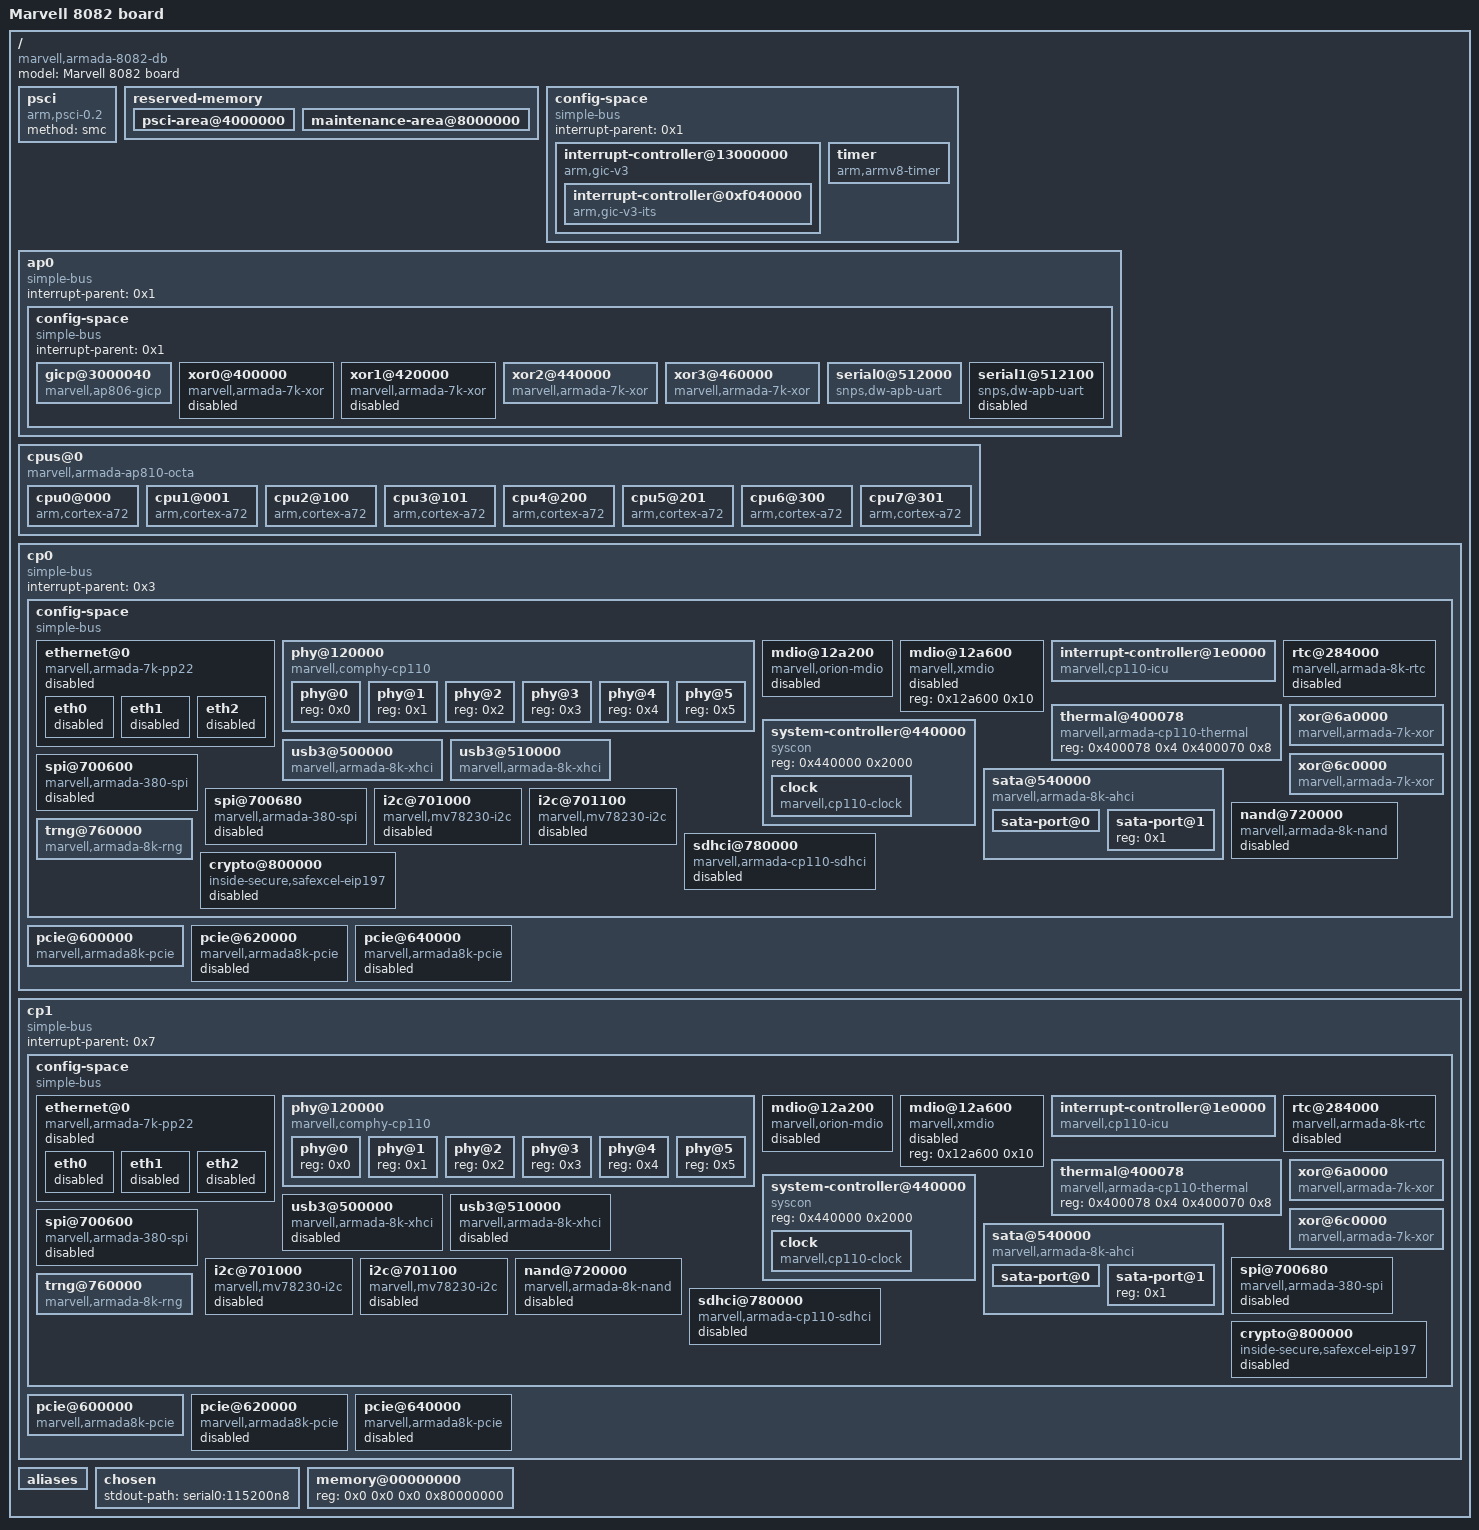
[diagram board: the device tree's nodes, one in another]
/dts-v1/;

/ {
    model = "Marvell 8082 board";
    compatible = "marvell,armada-8082-db", "marvell,armada-8082", "marvell,armada-ap810-octa", "marvell,armada-ap810";
    #address-cells = <0x2>;
    #size-cells = <0x2>;

    psci {
        compatible = "arm,psci-0.2";
        method = "smc";
    };

    reserved-memory {
        #address-cells = <0x2>;
        #size-cells = <0x2>;
        ranges;

        psci-area@4000000 {
            reg = <0x0 0x4000000 0x0 0x200000>;
            no-map;
        };

        maintenance-area@8000000 {
            reg = <0x0 0x8000000 0x0 0x100000>;
            no-map;
        };
    };

    config-space {
        #address-cells = <0x1>;
        #size-cells = <0x1>;
        compatible = "simple-bus";
        ranges = <0x0 0x0 0xdc000000 0x14000000>;
        interrupt-parent = <0x1>;

        interrupt-controller@13000000 {
            compatible = "arm,gic-v3";
            #interrupt-cells = <0x3>;
            #address-cells = <0x1>;
            #size-cells = <0x1>;
            interrupt-controller;
            interrupts = <0x1 0x9 0x4>;
            ranges;
            reg = <0x13000000 0x10000 0x13060000 0x100000 0x100c0000 0x2000 0x100d0000 0x1000 0x100e0000 0x2000>;
            linux,phandle = <0x1>;
            phandle = <0x1>;

            interrupt-controller@0xf040000 {
                compatible = "arm,gic-v3-its";
                msi-controller;
                #msi-cells = <0x1>;
                reg = <0xf040000 0x20000>;
                linux,phandle = <0x2>;
                phandle = <0x2>;
            };
        };

        timer {
            compatible = "arm,armv8-timer";
            interrupts = <0x1 0xd 0x8 0x1 0xe 0x8 0x1 0xb 0x8 0x1 0xa 0x8>;
        };
    };

    ap0 {
        #address-cells = <0x2>;
        #size-cells = <0x2>;
        compatible = "simple-bus";
        interrupt-parent = <0x1>;
        ranges;

        config-space {
            #address-cells = <0x1>;
            #size-cells = <0x1>;
            compatible = "simple-bus";
            ranges = <0x0 0x0 0xe8000000 0x4000000>;
            interrupt-parent = <0x1>;

            gicp@3000040 {
                compatible = "marvell,ap806-gicp";
                reg = <0x3000040 0x10>;
                marvell,spi-ranges = <0x5c 0x40 0x9c 0x40>;
                msi-controller;
                linux,phandle = <0x6>;
                phandle = <0x6>;
            };

            xor0@400000 {
                compatible = "marvell,armada-7k-xor", "marvell,xor-v2";
                reg = <0x400000 0x1000 0x410000 0x1000>;
                msi-parent = <0x2 0x100>;
                dma-coherent;
                status = "disabled";
            };

            xor1@420000 {
                compatible = "marvell,armada-7k-xor", "marvell,xor-v2";
                reg = <0x420000 0x1000 0x430000 0x1000>;
                msi-parent = <0x2 0x101>;
                dma-coherent;
                status = "disabled";
            };

            xor2@440000 {
                compatible = "marvell,armada-7k-xor", "marvell,xor-v2";
                reg = <0x440000 0x1000 0x450000 0x1000>;
                msi-parent = <0x2 0x102>;
                dma-coherent;
            };

            xor3@460000 {
                compatible = "marvell,armada-7k-xor", "marvell,xor-v2";
                reg = <0x460000 0x1000 0x470000 0x1000>;
                msi-parent = <0x2 0x103>;
                dma-coherent;
            };

            serial0@512000 {
                compatible = "snps,dw-apb-uart";
                reg = <0x512000 0x100>;
                reg-shift = <0x2>;
                interrupts = <0x0 0x16 0x4>;
                reg-io-width = <0x1>;
                status = "okay";
                clock-frequency = <0xbebc200>;
            };

            serial1@512100 {
                compatible = "snps,dw-apb-uart";
                reg = <0x512100 0x100>;
                reg-shift = <0x2>;
                interrupts = <0x0 0x17 0x4>;
                reg-io-width = <0x1>;
                status = "disabled";
            };
        };
    };

    cpus@0 {
        #address-cells = <0x1>;
        #size-cells = <0x0>;
        compatible = "marvell,armada-ap810-octa";

        cpu0@000 {
            device_type = "cpu";
            compatible = "arm,cortex-a72", "arm,armv8";
            reg = <0x0>;
            enable-method = "psci";
            numa-node-id = <0x0>;
        };

        cpu1@001 {
            device_type = "cpu";
            compatible = "arm,cortex-a72", "arm,armv8";
            reg = <0x1>;
            enable-method = "psci";
            numa-node-id = <0x0>;
        };

        cpu2@100 {
            device_type = "cpu";
            compatible = "arm,cortex-a72", "arm,armv8";
            reg = <0x100>;
            enable-method = "psci";
            numa-node-id = <0x0>;
        };

        cpu3@101 {
            device_type = "cpu";
            compatible = "arm,cortex-a72", "arm,armv8";
            reg = <0x101>;
            enable-method = "psci";
            numa-node-id = <0x0>;
        };

        cpu4@200 {
            device_type = "cpu";
            compatible = "arm,cortex-a72", "arm,armv8";
            reg = <0x200>;
            enable-method = "psci";
            numa-node-id = <0x0>;
        };

        cpu5@201 {
            device_type = "cpu";
            compatible = "arm,cortex-a72", "arm,armv8";
            reg = <0x201>;
            enable-method = "psci";
            numa-node-id = <0x0>;
        };

        cpu6@300 {
            device_type = "cpu";
            compatible = "arm,cortex-a72", "arm,armv8";
            reg = <0x300>;
            enable-method = "psci";
            numa-node-id = <0x0>;
        };

        cpu7@301 {
            device_type = "cpu";
            compatible = "arm,cortex-a72", "arm,armv8";
            reg = <0x301>;
            enable-method = "psci";
            numa-node-id = <0x0>;
        };
    };

    cp0 {
        #address-cells = <0x2>;
        #size-cells = <0x2>;
        compatible = "simple-bus";
        interrupt-parent = <0x3>;
        ranges;

        config-space {
            #address-cells = <0x1>;
            #size-cells = <0x1>;
            compatible = "simple-bus";
            ranges = <0x0 0x81 0x0 0x2000000>;

            ethernet@0 {
                compatible = "marvell,armada-7k-pp22";
                reg = <0x0 0x100000 0x129000 0xb000>;
                clocks = <0x4 0x1 0x3 0x4 0x1 0x9 0x4 0x1 0x5 0x4 0x1 0x12>;
                clock-names = "pp_clk", "gop_clk", "mg_clk", "axi_clk";
                marvell,system-controller = <0x5>;
                status = "disabled";
                dma-coherent;

                eth0 {
                    interrupts = <0x0 0x27 0x4 0x0 0x2b 0x4 0x0 0x2f 0x4 0x0 0x33 0x4 0x0 0x37 0x4 0x0 0x81 0x4>;
                    interrupt-names = "tx-cpu0", "tx-cpu1", "tx-cpu2", "tx-cpu3", "rx-shared", "link";
                    port-id = <0x0>;
                    gop-port-id = <0x0>;
                    status = "disabled";
                };

                eth1 {
                    interrupts = <0x0 0x28 0x4 0x0 0x2c 0x4 0x0 0x30 0x4 0x0 0x34 0x4 0x0 0x38 0x4 0x0 0x80 0x4>;
                    interrupt-names = "tx-cpu0", "tx-cpu1", "tx-cpu2", "tx-cpu3", "rx-shared", "link";
                    port-id = <0x1>;
                    gop-port-id = <0x2>;
                    status = "disabled";
                };

                eth2 {
                    interrupts = <0x0 0x29 0x4 0x0 0x2d 0x4 0x0 0x31 0x4 0x0 0x35 0x4 0x0 0x39 0x4 0x0 0x7f 0x4>;
                    interrupt-names = "tx-cpu0", "tx-cpu1", "tx-cpu2", "tx-cpu3", "rx-shared", "link";
                    port-id = <0x2>;
                    gop-port-id = <0x3>;
                    status = "disabled";
                };
            };

            phy@120000 {
                compatible = "marvell,comphy-cp110";
                reg = <0x120000 0x6000>;
                marvell,system-controller = <0x5>;
                #address-cells = <0x1>;
                #size-cells = <0x0>;

                phy@0 {
                    reg = <0x0>;
                    #phy-cells = <0x1>;
                };

                phy@1 {
                    reg = <0x1>;
                    #phy-cells = <0x1>;
                };

                phy@2 {
                    reg = <0x2>;
                    #phy-cells = <0x1>;
                };

                phy@3 {
                    reg = <0x3>;
                    #phy-cells = <0x1>;
                };

                phy@4 {
                    reg = <0x4>;
                    #phy-cells = <0x1>;
                };

                phy@5 {
                    reg = <0x5>;
                    #phy-cells = <0x1>;
                };
            };

            mdio@12a200 {
                #address-cells = <0x1>;
                #size-cells = <0x0>;
                compatible = "marvell,orion-mdio";
                reg = <0x12a200 0x10>;
                clocks = <0x4 0x1 0x9 0x4 0x1 0x5 0x4 0x1 0x6 0x4 0x1 0x12>;
                status = "disabled";
            };

            mdio@12a600 {
                #address-cells = <0x1>;
                #size-cells = <0x0>;
                compatible = "marvell,xmdio";
                reg = <0x12a600 0x10>;
                status = "disabled";
            };

            interrupt-controller@1e0000 {
                compatible = "marvell,cp110-icu";
                reg = <0x1e0000 0x10>;
                #interrupt-cells = <0x3>;
                interrupt-controller;
                msi-parent = <0x6>;
                linux,phandle = <0x3>;
                phandle = <0x3>;
            };

            rtc@284000 {
                compatible = "marvell,armada-8k-rtc";
                reg = <0x284000 0x20 0x284080 0x24>;
                reg-names = "rtc", "rtc-soc";
                interrupts = <0x0 0x4d 0x4>;
                status = "disabled";
            };

            thermal@400078 {
                compatible = "marvell,armada-cp110-thermal";
                reg = <0x400078 0x4 0x400070 0x8>;
            };

            system-controller@440000 {
                compatible = "syscon", "simple-mfd";
                reg = <0x440000 0x2000>;
                linux,phandle = <0x5>;
                phandle = <0x5>;

                clock {
                    compatible = "marvell,cp110-clock";
                    #clock-cells = <0x2>;
                    linux,phandle = <0x4>;
                    phandle = <0x4>;
                };
            };

            usb3@500000 {
                compatible = "marvell,armada-8k-xhci", "generic-xhci";
                reg = <0x500000 0x4000>;
                dma-coherent;
                interrupts = <0x0 0x6a 0x4>;
                clocks = <0x4 0x1 0x16>;
                status = "okay";
            };

            usb3@510000 {
                compatible = "marvell,armada-8k-xhci", "generic-xhci";
                reg = <0x510000 0x4000>;
                dma-coherent;
                interrupts = <0x0 0x69 0x4>;
                clocks = <0x4 0x1 0x17>;
                status = "okay";
            };

            sata@540000 {
                compatible = "marvell,armada-8k-ahci", "generic-ahci";
                reg = <0x540000 0x30000>;
                dma-coherent;
                interrupts = <0x0 0x6b 0x4>;
                clocks = <0x4 0x1 0xf>;
                status = "okay";
                #address-cells = <0x1>;
                #size-cells = <0x0>;

                sata-port@0 {
                    reg = <0x0>;
                    satus = "disabled";
                };

                sata-port@1 {
                    reg = <0x1>;
                    status = "okay";
                };
            };

            xor@6a0000 {
                compatible = "marvell,armada-7k-xor", "marvell,xor-v2";
                reg = <0x6a0000 0x1000 0x6b0000 0x1000>;
                dma-coherent;
                msi-parent = <0x2 0x89>;
                clocks = <0x4 0x1 0x8>;
            };

            xor@6c0000 {
                compatible = "marvell,armada-7k-xor", "marvell,xor-v2";
                reg = <0x6c0000 0x1000 0x6d0000 0x1000>;
                dma-coherent;
                msi-parent = <0x2 0x8a>;
                clocks = <0x4 0x1 0x7>;
            };

            spi@700600 {
                compatible = "marvell,armada-380-spi";
                reg = <0x700600 0x50>;
                #address-cells = <0x1>;
                #size-cells = <0x0>;
                cell-index = <0x1>;
                clocks = <0x4 0x1 0x15>;
                status = "disabled";
            };

            spi@700680 {
                compatible = "marvell,armada-380-spi";
                reg = <0x700680 0x50>;
                #address-cells = <0x1>;
                #size-cells = <0x0>;
                cell-index = <0x2>;
                clocks = <0x4 0x1 0x15>;
                status = "disabled";
            };

            i2c@701000 {
                compatible = "marvell,mv78230-i2c";
                reg = <0x701000 0x20>;
                #address-cells = <0x1>;
                #size-cells = <0x0>;
                interrupts = <0x0 0x78 0x4>;
                clocks = <0x4 0x1 0x15>;
                status = "disabled";
            };

            i2c@701100 {
                compatible = "marvell,mv78230-i2c";
                reg = <0x701100 0x20>;
                #address-cells = <0x1>;
                #size-cells = <0x0>;
                interrupts = <0x0 0x79 0x4>;
                clocks = <0x4 0x1 0x15>;
                status = "disabled";
            };

            nand@720000 {
                compatible = "marvell,armada-8k-nand", "marvell,armada370-nand";
                reg = <0x720000 0x54>;
                #address-cells = <0x1>;
                #size-cells = <0x1>;
                interrupts = <0x0 0x73 0x4>;
                clocks = <0x4 0x1 0x2>;
                marvell,system-controller = <0x5>;
                status = "disabled";
            };

            trng@760000 {
                compatible = "marvell,armada-8k-rng", "inside-secure,safexcel-eip76";
                reg = <0x760000 0x7d>;
                interrupts = <0x0 0x5f 0x4>;
                clocks = <0x4 0x1 0x19>;
                status = "okay";
            };

            sdhci@780000 {
                compatible = "marvell,armada-cp110-sdhci";
                reg = <0x780000 0x300>;
                interrupts = <0x0 0x1b 0x4>;
                clock-names = "core", "axi";
                clocks = <0x4 0x1 0x4 0x4 0x1 0x12>;
                dma-coherent;
                status = "disabled";
            };

            crypto@800000 {
                compatible = "inside-secure,safexcel-eip197";
                reg = <0x800000 0x200000>;
                interrupts = <0x0 0x57 0x4 0x0 0x58 0x4 0x0 0x59 0x4 0x0 0x5a 0x4 0x0 0x5b 0x4 0x0 0x5c 0x4>;
                interrupt-names = "mem", "ring0", "ring1", "ring2", "ring3", "eip";
                clocks = <0x4 0x1 0x1a>;
                dma-coherent;
                status = "disabled";
            };
        };

        pcie@600000 {
            compatible = "marvell,armada8k-pcie", "snps,dw-pcie";
            reg = <0x81 0x600000 0x0 0x10000 0x82 0xfff00000 0x0 0x80000>;
            reg-names = "ctrl", "config";
            #address-cells = <0x3>;
            #size-cells = <0x2>;
            #interrupt-cells = <0x1>;
            device_type = "pci";
            dma-coherent;
            msi-parent = <0x2>;
            bus-range = <0x0 0xff>;
            ranges = <0x81000000 0x0 0xfffe0000 0x82 0xfffe0000 0x0 0x10000 0x83000000 0x0 0x0 0x82 0x0 0x0 0xfff00000>;
            interrupt-map-mask = <0x0 0x0 0x0 0x0>;
            interrupt-map = <0x0 0x0 0x0 0x0 0x3 0x0 0x16 0x4>;
            interrupts = <0x0 0x16 0x4>;
            num-lanes = <0x1>;
            clocks = <0x4 0x1 0xd>;
            status = "okay";
        };

        pcie@620000 {
            compatible = "marvell,armada8k-pcie", "snps,dw-pcie";
            reg = <0x81 0x620000 0x0 0x10000 0x84 0xfff00000 0x0 0x80000>;
            reg-names = "ctrl", "config";
            #address-cells = <0x3>;
            #size-cells = <0x2>;
            #interrupt-cells = <0x1>;
            device_type = "pci";
            dma-coherent;
            msi-parent = <0x2>;
            bus-range = <0x0 0xff>;
            ranges = <0x81000000 0x0 0xfffe0000 0x84 0xfffe0000 0x0 0x10000 0x83000000 0x0 0x0 0x84 0x0 0x0 0xfff00000>;
            interrupt-map-mask = <0x0 0x0 0x0 0x0>;
            interrupt-map = <0x0 0x0 0x0 0x0 0x3 0x0 0x18 0x4>;
            interrupts = <0x0 0x18 0x4>;
            num-lanes = <0x1>;
            clocks = <0x4 0x1 0xb>;
            status = "disabled";
        };

        pcie@640000 {
            compatible = "marvell,armada8k-pcie", "snps,dw-pcie";
            reg = <0x81 0x640000 0x0 0x10000 0x86 0xfff00000 0x0 0x80000>;
            reg-names = "ctrl", "config";
            #address-cells = <0x3>;
            #size-cells = <0x2>;
            #interrupt-cells = <0x1>;
            device_type = "pci";
            dma-coherent;
            msi-parent = <0x2>;
            bus-range = <0x0 0xff>;
            ranges = <0x81000000 0x0 0xfffe0000 0x86 0xfffe0000 0x0 0x10000 0x83000000 0x0 0x0 0x86 0x0 0x0 0xfff00000>;
            interrupt-map-mask = <0x0 0x0 0x0 0x0>;
            interrupt-map = <0x0 0x0 0x0 0x0 0x3 0x0 0x17 0x4>;
            interrupts = <0x0 0x17 0x4>;
            num-lanes = <0x1>;
            clocks = <0x4 0x1 0xc>;
            status = "disabled";
        };
    };

    cp1 {
        #address-cells = <0x2>;
        #size-cells = <0x2>;
        compatible = "simple-bus";
        interrupt-parent = <0x7>;
        ranges;

        config-space {
            #address-cells = <0x1>;
            #size-cells = <0x1>;
            compatible = "simple-bus";
            ranges = <0x0 0x88 0x0 0x2000000>;

            ethernet@0 {
                compatible = "marvell,armada-7k-pp22";
                reg = <0x0 0x100000 0x129000 0xb000>;
                clocks = <0x8 0x1 0x3 0x8 0x1 0x9 0x8 0x1 0x5 0x8 0x1 0x12>;
                clock-names = "pp_clk", "gop_clk", "mg_clk", "axi_clk";
                marvell,system-controller = <0x9>;
                status = "disabled";
                dma-coherent;

                eth0 {
                    interrupts = <0x0 0x27 0x4 0x0 0x2b 0x4 0x0 0x2f 0x4 0x0 0x33 0x4 0x0 0x37 0x4 0x0 0x81 0x4>;
                    interrupt-names = "tx-cpu0", "tx-cpu1", "tx-cpu2", "tx-cpu3", "rx-shared", "link";
                    port-id = <0x0>;
                    gop-port-id = <0x0>;
                    status = "disabled";
                };

                eth1 {
                    interrupts = <0x0 0x28 0x4 0x0 0x2c 0x4 0x0 0x30 0x4 0x0 0x34 0x4 0x0 0x38 0x4 0x0 0x80 0x4>;
                    interrupt-names = "tx-cpu0", "tx-cpu1", "tx-cpu2", "tx-cpu3", "rx-shared", "link";
                    port-id = <0x1>;
                    gop-port-id = <0x2>;
                    status = "disabled";
                };

                eth2 {
                    interrupts = <0x0 0x29 0x4 0x0 0x2d 0x4 0x0 0x31 0x4 0x0 0x35 0x4 0x0 0x39 0x4 0x0 0x7f 0x4>;
                    interrupt-names = "tx-cpu0", "tx-cpu1", "tx-cpu2", "tx-cpu3", "rx-shared", "link";
                    port-id = <0x2>;
                    gop-port-id = <0x3>;
                    status = "disabled";
                };
            };

            phy@120000 {
                compatible = "marvell,comphy-cp110";
                reg = <0x120000 0x6000>;
                marvell,system-controller = <0x9>;
                #address-cells = <0x1>;
                #size-cells = <0x0>;

                phy@0 {
                    reg = <0x0>;
                    #phy-cells = <0x1>;
                };

                phy@1 {
                    reg = <0x1>;
                    #phy-cells = <0x1>;
                };

                phy@2 {
                    reg = <0x2>;
                    #phy-cells = <0x1>;
                };

                phy@3 {
                    reg = <0x3>;
                    #phy-cells = <0x1>;
                };

                phy@4 {
                    reg = <0x4>;
                    #phy-cells = <0x1>;
                };

                phy@5 {
                    reg = <0x5>;
                    #phy-cells = <0x1>;
                };
            };

            mdio@12a200 {
                #address-cells = <0x1>;
                #size-cells = <0x0>;
                compatible = "marvell,orion-mdio";
                reg = <0x12a200 0x10>;
                clocks = <0x8 0x1 0x9 0x8 0x1 0x5 0x8 0x1 0x6 0x8 0x1 0x12>;
                status = "disabled";
            };

            mdio@12a600 {
                #address-cells = <0x1>;
                #size-cells = <0x0>;
                compatible = "marvell,xmdio";
                reg = <0x12a600 0x10>;
                status = "disabled";
            };

            interrupt-controller@1e0000 {
                compatible = "marvell,cp110-icu";
                reg = <0x1e0000 0x10>;
                #interrupt-cells = <0x3>;
                interrupt-controller;
                msi-parent = <0x6>;
                linux,phandle = <0x7>;
                phandle = <0x7>;
            };

            rtc@284000 {
                compatible = "marvell,armada-8k-rtc";
                reg = <0x284000 0x20 0x284080 0x24>;
                reg-names = "rtc", "rtc-soc";
                interrupts = <0x0 0x4d 0x4>;
                status = "disabled";
            };

            thermal@400078 {
                compatible = "marvell,armada-cp110-thermal";
                reg = <0x400078 0x4 0x400070 0x8>;
            };

            system-controller@440000 {
                compatible = "syscon", "simple-mfd";
                reg = <0x440000 0x2000>;
                linux,phandle = <0x9>;
                phandle = <0x9>;

                clock {
                    compatible = "marvell,cp110-clock";
                    #clock-cells = <0x2>;
                    linux,phandle = <0x8>;
                    phandle = <0x8>;
                };
            };

            usb3@500000 {
                compatible = "marvell,armada-8k-xhci", "generic-xhci";
                reg = <0x500000 0x4000>;
                dma-coherent;
                interrupts = <0x0 0x6a 0x4>;
                clocks = <0x8 0x1 0x16>;
                status = "disabled";
            };

            usb3@510000 {
                compatible = "marvell,armada-8k-xhci", "generic-xhci";
                reg = <0x510000 0x4000>;
                dma-coherent;
                interrupts = <0x0 0x69 0x4>;
                clocks = <0x8 0x1 0x17>;
                status = "disabled";
            };

            sata@540000 {
                compatible = "marvell,armada-8k-ahci", "generic-ahci";
                reg = <0x540000 0x30000>;
                dma-coherent;
                interrupts = <0x0 0x6b 0x4>;
                clocks = <0x8 0x1 0xf>;
                status = "okay";
                #address-cells = <0x1>;
                #size-cells = <0x0>;

                sata-port@0 {
                    reg = <0x0>;
                    satus = "disabled";
                };

                sata-port@1 {
                    reg = <0x1>;
                    status = "okay";
                };
            };

            xor@6a0000 {
                compatible = "marvell,armada-7k-xor", "marvell,xor-v2";
                reg = <0x6a0000 0x1000 0x6b0000 0x1000>;
                dma-coherent;
                msi-parent = <0x2 0x89>;
                clocks = <0x8 0x1 0x8>;
            };

            xor@6c0000 {
                compatible = "marvell,armada-7k-xor", "marvell,xor-v2";
                reg = <0x6c0000 0x1000 0x6d0000 0x1000>;
                dma-coherent;
                msi-parent = <0x2 0x8a>;
                clocks = <0x8 0x1 0x7>;
            };

            spi@700600 {
                compatible = "marvell,armada-380-spi";
                reg = <0x700600 0x50>;
                #address-cells = <0x1>;
                #size-cells = <0x0>;
                cell-index = <0x3>;
                clocks = <0x8 0x1 0x15>;
                status = "disabled";
            };

            spi@700680 {
                compatible = "marvell,armada-380-spi";
                reg = <0x700680 0x50>;
                #address-cells = <0x1>;
                #size-cells = <0x0>;
                cell-index = <0x4>;
                clocks = <0x8 0x1 0x15>;
                status = "disabled";
            };

            i2c@701000 {
                compatible = "marvell,mv78230-i2c";
                reg = <0x701000 0x20>;
                #address-cells = <0x1>;
                #size-cells = <0x0>;
                interrupts = <0x0 0x78 0x4>;
                clocks = <0x8 0x1 0x15>;
                status = "disabled";
            };

            i2c@701100 {
                compatible = "marvell,mv78230-i2c";
                reg = <0x701100 0x20>;
                #address-cells = <0x1>;
                #size-cells = <0x0>;
                interrupts = <0x0 0x79 0x4>;
                clocks = <0x8 0x1 0x15>;
                status = "disabled";
            };

            nand@720000 {
                compatible = "marvell,armada-8k-nand", "marvell,armada370-nand";
                reg = <0x720000 0x54>;
                #address-cells = <0x1>;
                #size-cells = <0x1>;
                interrupts = <0x0 0x73 0x4>;
                clocks = <0x8 0x1 0x2>;
                marvell,system-controller = <0x9>;
                status = "disabled";
            };

            trng@760000 {
                compatible = "marvell,armada-8k-rng", "inside-secure,safexcel-eip76";
                reg = <0x760000 0x7d>;
                interrupts = <0x0 0x5f 0x4>;
                clocks = <0x8 0x1 0x19>;
                status = "okay";
            };

            sdhci@780000 {
                compatible = "marvell,armada-cp110-sdhci";
                reg = <0x780000 0x300>;
                interrupts = <0x0 0x1b 0x4>;
                clock-names = "core", "axi";
                clocks = <0x8 0x1 0x4 0x8 0x1 0x12>;
                dma-coherent;
                status = "disabled";
            };

            crypto@800000 {
                compatible = "inside-secure,safexcel-eip197";
                reg = <0x800000 0x200000>;
                interrupts = <0x0 0x57 0x4 0x0 0x58 0x4 0x0 0x59 0x4 0x0 0x5a 0x4 0x0 0x5b 0x4 0x0 0x5c 0x4>;
                interrupt-names = "mem", "ring0", "ring1", "ring2", "ring3", "eip";
                clocks = <0x8 0x1 0x1a>;
                dma-coherent;
                status = "disabled";
            };
        };

        pcie@600000 {
            compatible = "marvell,armada8k-pcie", "snps,dw-pcie";
            reg = <0x88 0x600000 0x0 0x10000 0x89 0xfff00000 0x0 0x80000>;
            reg-names = "ctrl", "config";
            #address-cells = <0x3>;
            #size-cells = <0x2>;
            #interrupt-cells = <0x1>;
            device_type = "pci";
            dma-coherent;
            msi-parent = <0x2>;
            bus-range = <0x0 0xff>;
            ranges = <0x81000000 0x0 0xfffe0000 0x89 0xfffe0000 0x0 0x10000 0x83000000 0x0 0x0 0x89 0x0 0x0 0xfff00000>;
            interrupt-map-mask = <0x0 0x0 0x0 0x0>;
            interrupt-map = <0x0 0x0 0x0 0x0 0x7 0x0 0x16 0x4>;
            interrupts = <0x0 0x16 0x4>;
            num-lanes = <0x1>;
            clocks = <0x8 0x1 0xd>;
            status = "okay";
        };

        pcie@620000 {
            compatible = "marvell,armada8k-pcie", "snps,dw-pcie";
            reg = <0x88 0x620000 0x0 0x10000 0x8b 0xfff00000 0x0 0x80000>;
            reg-names = "ctrl", "config";
            #address-cells = <0x3>;
            #size-cells = <0x2>;
            #interrupt-cells = <0x1>;
            device_type = "pci";
            dma-coherent;
            msi-parent = <0x2>;
            bus-range = <0x0 0xff>;
            ranges = <0x81000000 0x0 0xfffe0000 0x8b 0xfffe0000 0x0 0x10000 0x83000000 0x0 0x0 0x8b 0x0 0x0 0xfff00000>;
            interrupt-map-mask = <0x0 0x0 0x0 0x0>;
            interrupt-map = <0x0 0x0 0x0 0x0 0x7 0x0 0x18 0x4>;
            interrupts = <0x0 0x18 0x4>;
            num-lanes = <0x1>;
            clocks = <0x8 0x1 0xb>;
            status = "disabled";
        };

        pcie@640000 {
            compatible = "marvell,armada8k-pcie", "snps,dw-pcie";
            reg = <0x88 0x640000 0x0 0x10000 0x8d 0xfff00000 0x0 0x80000>;
            reg-names = "ctrl", "config";
            #address-cells = <0x3>;
            #size-cells = <0x2>;
            #interrupt-cells = <0x1>;
            device_type = "pci";
            dma-coherent;
            msi-parent = <0x2>;
            bus-range = <0x0 0xff>;
            ranges = <0x81000000 0x0 0xfffe0000 0x8d 0xfffe0000 0x0 0x10000 0x83000000 0x0 0x0 0x8d 0x0 0x0 0xfff00000>;
            interrupt-map-mask = <0x0 0x0 0x0 0x0>;
            interrupt-map = <0x0 0x0 0x0 0x0 0x7 0x0 0x17 0x4>;
            interrupts = <0x0 0x17 0x4>;
            num-lanes = <0x1>;
            clocks = <0x8 0x1 0xc>;
            status = "disabled";
        };
    };

    aliases {
        serial0 = "/ap0/config-space/serial0@512000";
        serial1 = "/ap0/config-space/serial1@512100";
    };

    chosen {
        stdout-path = "serial0:115200n8";
    };

    memory@00000000 {
        device_type = "memory";
        reg = <0x0 0x0 0x0 0x80000000>;
    };
};
